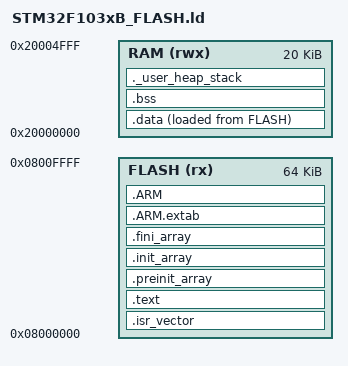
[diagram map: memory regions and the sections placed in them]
/* Linker script for STM32F103xB (medium-density, 64KB flash / 20KB SRAM) */

ENTRY(Reset_Handler)

MEMORY
{
  FLASH (rx)  : ORIGIN = 0x08000000, LENGTH = 64K
  RAM   (rwx) : ORIGIN = 0x20000000, LENGTH = 20K
}

_estack = ORIGIN(RAM) + LENGTH(RAM);

SECTIONS
{
  .isr_vector :
  {
    . = ALIGN(4);
    KEEP(*(.isr_vector))
    . = ALIGN(4);
  } > FLASH

  .text :
  {
    . = ALIGN(4);
    KEEP(*(.init))
    *(.text)
    *(.text*)
    KEEP(*(.fini))
    *(.rodata)
    *(.rodata*)
    . = ALIGN(4);
    _etext = .;
  } > FLASH

  .preinit_array :
  {
    . = ALIGN(4);
    PROVIDE_HIDDEN(__preinit_array_start = .);
    KEEP(*(.preinit_array*))
    PROVIDE_HIDDEN(__preinit_array_end = .);
  } > FLASH

  .init_array :
  {
    . = ALIGN(4);
    PROVIDE_HIDDEN(__init_array_start = .);
    KEEP(*(SORT(.init_array.*)))
    KEEP(*(.init_array*))
    PROVIDE_HIDDEN(__init_array_end = .);
    . = ALIGN(4);
  } > FLASH

  .fini_array :
  {
    . = ALIGN(4);
    PROVIDE_HIDDEN(__fini_array_start = .);
    KEEP(*(SORT(.fini_array.*)))
    KEEP(*(.fini_array*))
    PROVIDE_HIDDEN(__fini_array_end = .);
  } > FLASH

  .ARM.extab :
  {
    *(.ARM.extab* .gnu.linkonce.armextab.*)
  } > FLASH

  .ARM :
  {
    __exidx_start = .;
    *(.ARM.exidx*)
    __exidx_end = .;
  } > FLASH

  _sidata = LOADADDR(.data);

  .data :
  {
    . = ALIGN(4);
    _sdata = .;
    *(.data)
    *(.data*)
    . = ALIGN(4);
    _edata = .;
  } > RAM AT> FLASH

  .bss :
  {
    . = ALIGN(4);
    _sbss = .;
    *(.bss)
    *(.bss*)
    *(COMMON)
    . = ALIGN(4);
    _ebss = .;
  } > RAM

  ._user_heap_stack :
  {
    . = ALIGN(8);
    end = .;
    . = . + 4096; /* minimum heap+stack headroom */
    . = ALIGN(8);
  } > RAM
}
